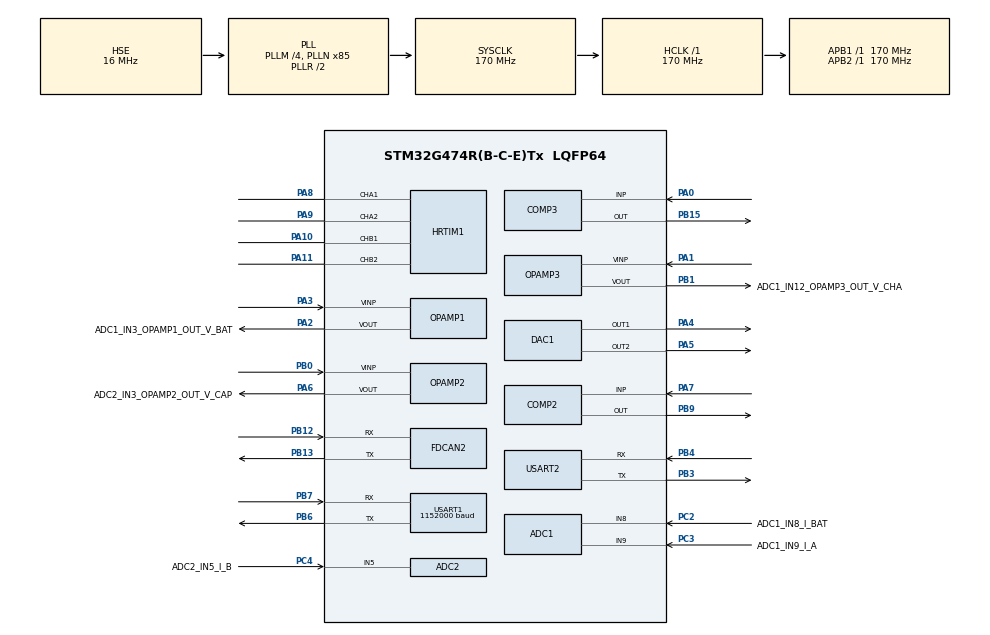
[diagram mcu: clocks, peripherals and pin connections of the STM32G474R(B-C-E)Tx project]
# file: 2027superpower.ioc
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ADC1.AWD1FilteringConfig=ADC_AWD_FILTERING_NONE
ADC1.AWD2ITMode=DISABLE
ADC1.AWDChannel-4\#ChannelRegularConversion=ADC_CHANNEL_8
ADC1.AWDChannel-5\#ChannelRegularConversion=ADC_CHANNEL_12
ADC1.Channel-3\#ChannelRegularConversion=ADC_CHANNEL_9
ADC1.Channel-4\#ChannelRegularConversion=ADC_CHANNEL_8
ADC1.Channel-5\#ChannelRegularConversion=ADC_CHANNEL_12
ADC1.Channel-7\#ChannelRegularConversion=ADC_CHANNEL_3
ADC1.DMAAccessModeView=ENABLE
ADC1.DMAContinuousRequests=ENABLE
ADC1.DiscontinuousConvMode=DISABLE
ADC1.EnableAnalogWatchDog1=true
ADC1.EnableAnalogWatchDog2=true
ADC1.EnableAnalogWatchDog3=true
ADC1.EnableInjectedConversion=DISABLE
ADC1.ExternalTrigConv=ADC_EXTERNALTRIG_HRTIM_TRG1
ADC1.Mode=ADC_DUALMODE_REGSIMULT
ADC1.MonitoredBy-4\#ChannelRegularConversion=ADC_ANALOGWATCHDOG_2
ADC1.MonitoredBy-5\#ChannelRegularConversion=ADC_ANALOGWATCHDOG_3
ADC1.NbrOfConversion=4
ADC1.NbrOfConversionFlag=1
ADC1.OffsetNumber-3\#ChannelRegularConversion=ADC_OFFSET_NONE
ADC1.OffsetNumber-4\#ChannelRegularConversion=ADC_OFFSET_NONE
ADC1.OffsetNumber-5\#ChannelRegularConversion=ADC_OFFSET_NONE
ADC1.OffsetNumber-7\#ChannelRegularConversion=ADC_OFFSET_NONE
ADC1.Overrun=ADC_OVR_DATA_OVERWRITTEN
ADC1.Rank-3\#ChannelRegularConversion=1
ADC1.Rank-4\#ChannelRegularConversion=2
ADC1.Rank-5\#ChannelRegularConversion=3
ADC1.Rank-7\#ChannelRegularConversion=4
ADC1.Rank1_Channel=ADC_CHANNEL_3
ADC1.RegFilteringConfig-4\#ChannelRegularConversion=ADC_AWD_FILTERING_NONE
ADC1.RegFilteringConfig-5\#ChannelRegularConversion=ADC_AWD_FILTERING_NONE
ADC1.SamplingTime-3\#ChannelRegularConversion=ADC_SAMPLETIME_12CYCLES_5
ADC1.SamplingTime-4\#ChannelRegularConversion=ADC_SAMPLETIME_12CYCLES_5
ADC1.SamplingTime-5\#ChannelRegularConversion=ADC_SAMPLETIME_12CYCLES_5
ADC1.SamplingTime-7\#ChannelRegularConversion=ADC_SAMPLETIME_12CYCLES_5
ADC1.WDG2ChannelR2=ADC_CHANNEL_8
ADC1.WDG3ChannelR3=ADC_CHANNEL_12
ADC1.WatchdogChannel=ADC_CHANNEL_9
ADC1.WatchdogMode2=ADC_ANALOGWATCHDOG_SINGLE_REGINJEC
ADC1.WatchdogMode3=ADC_ANALOGWATCHDOG_SINGLE_REGINJEC
ADC1.master=1
ADC2.AWD1FilteringConfig=ADC_AWD_FILTERING_NONE
ADC2.AWDChannel-2\#ChannelRegularConversion=ADC_CHANNEL_3
ADC2.Channel-0\#ChannelRegularConversion=ADC_CHANNEL_5
ADC2.Channel-1\#ChannelRegularConversion=ADC_CHANNEL_5
ADC2.Channel-2\#ChannelRegularConversion=ADC_CHANNEL_3
ADC2.Channel-4\#ChannelRegularConversion=ADC_CHANNEL_3
ADC2.DMAAccessModeView=ENABLE
ADC2.EnableAnalogWatchDog1=true
ADC2.EnableAnalogWatchDog2=true
ADC2.EnableAnalogWatchDog3=true
ADC2.Mode=ADC_DUALMODE_REGSIMULT
ADC2.MonitoredBy-2\#ChannelRegularConversion=ADC_ANALOGWATCHDOG_2
ADC2.NbrOfConversion=4
ADC2.NbrOfConversionFlag=1
ADC2.OffsetNumber-0\#ChannelRegularConversion=ADC_OFFSET_NONE
ADC2.OffsetNumber-1\#ChannelRegularConversion=ADC_OFFSET_NONE
ADC2.OffsetNumber-2\#ChannelRegularConversion=ADC_OFFSET_NONE
ADC2.OffsetNumber-4\#ChannelRegularConversion=ADC_OFFSET_NONE
ADC2.OversamplingMode=DISABLE
ADC2.Rank-0\#ChannelRegularConversion=1
ADC2.Rank-1\#ChannelRegularConversion=2
ADC2.Rank-2\#ChannelRegularConversion=3
ADC2.Rank-4\#ChannelRegularConversion=4
ADC2.RegFilteringConfig-2\#ChannelRegularConversion=ADC_AWD_FILTERING_NONE
ADC2.SamplingTime-0\#ChannelRegularConversion=ADC_SAMPLETIME_12CYCLES_5
ADC2.SamplingTime-1\#ChannelRegularConversion=ADC_SAMPLETIME_12CYCLES_5
ADC2.SamplingTime-2\#ChannelRegularConversion=ADC_SAMPLETIME_12CYCLES_5
ADC2.SamplingTime-4\#ChannelRegularConversion=ADC_SAMPLETIME_12CYCLES_5
ADC2.WDG2ChannelR3=ADC_CHANNEL_3
ADC2.WatchdogChannel=ADC_CHANNEL_5
ADC2.WatchdogMode=ADC_ANALOGWATCHDOG_SINGLE_REG
ADC2.WatchdogMode2=ADC_ANALOGWATCHDOG_SINGLE_REGINJEC
ADC2.WatchdogMode3=ADC_ANALOGWATCHDOG_SINGLE_REGINJEC
ADC5.Channel-0\#ChannelRegularConversion=ADC_CHANNEL_VREFINT
ADC5.Channel-1\#ChannelRegularConversion=ADC_CHANNEL_TEMPSENSOR_ADC5
ADC5.ContinuousConvMode=ENABLE
ADC5.DMAContinuousRequests=ENABLE
ADC5.NbrOfConversion=2
ADC5.NbrOfConversionFlag=1
ADC5.OffsetNumber-0\#ChannelRegularConversion=ADC_OFFSET_NONE
ADC5.OffsetNumber-1\#ChannelRegularConversion=ADC_OFFSET_NONE
ADC5.Overrun=ADC_OVR_DATA_OVERWRITTEN
ADC5.OversamplingMode=ENABLE
ADC5.Rank-0\#ChannelRegularConversion=1
ADC5.Rank-1\#ChannelRegularConversion=2
ADC5.Ratio=ADC_OVERSAMPLING_RATIO_256
ADC5.RightBitShift=ADC_RIGHTBITSHIFT_8
ADC5.SamplingTime-0\#ChannelRegularConversion=ADC_SAMPLETIME_640CYCLES_5
ADC5.SamplingTime-1\#ChannelRegularConversion=ADC_SAMPLETIME_640CYCLES_5
COMP2.OutputPol=COMP_OUTPUTPOL_NONINVERTED
DAC1.DAC_Channel-DAC_OUT2_ExtAndInt=DAC_CHANNEL_2
DAC1.DAC_HighFrequency_OUT1-DAC_OUT1_ExtAndInt=DAC_HIGH_FREQUENCY_INTERFACE_MODE_ABOVE_160MHZ
DAC1.DAC_Trigger2_OUT1-DAC_OUT1_ExtAndInt=DAC_TRIGGER_HRTIM_STEP_TRG2
DAC1.DAC_Trigger2_OUT2-DAC_OUT2_ExtAndInt=DAC_TRIGGER_HRTIM_STEP_TRG1
DAC1.DAC_Trigger_OUT1-DAC_OUT1_ExtAndInt=DAC_TRIGGER_HRTIM_RST_TRG2
DAC1.DAC_Trigger_OUT2-DAC_OUT2_ExtAndInt=DAC_TRIGGER_HRTIM_RST_TRG1
DAC1.WaveGeneration_OUT1-DAC_OUT1_ExtAndInt=SawtoothWaveGenerate
Dma.ADC1.4.Direction=DMA_PERIPH_TO_MEMORY
Dma.ADC1.4.EventEnable=DISABLE
Dma.ADC1.4.Instance=DMA1_Channel1
Dma.ADC1.4.MemDataAlignment=DMA_MDATAALIGN_WORD
Dma.ADC1.4.MemInc=DMA_MINC_ENABLE
Dma.ADC1.4.Mode=DMA_CIRCULAR
Dma.ADC1.4.PeriphDataAlignment=DMA_PDATAALIGN_WORD
Dma.ADC1.4.PeriphInc=DMA_PINC_DISABLE
Dma.ADC1.4.Polarity=HAL_DMAMUX_REQ_GEN_RISING
Dma.ADC1.4.Priority=DMA_PRIORITY_VERY_HIGH
Dma.ADC1.4.RequestNumber=1
Dma.ADC1.4.SignalID=NONE
Dma.ADC1.4.SyncEnable=DISABLE
Dma.ADC1.4.SyncPolarity=HAL_DMAMUX_SYNC_NO_EVENT
Dma.ADC1.4.SyncRequestNumber=1
Dma.ADC1.4.SyncSignalID=NONE
Dma.ADC5.5.Direction=DMA_PERIPH_TO_MEMORY
Dma.ADC5.5.EventEnable=DISABLE
Dma.ADC5.5.Instance=DMA1_Channel6
Dma.ADC5.5.MemDataAlignment=DMA_MDATAALIGN_HALFWORD
Dma.ADC5.5.MemInc=DMA_MINC_ENABLE
Dma.ADC5.5.Mode=DMA_CIRCULAR
Dma.ADC5.5.PeriphDataAlignment=DMA_PDATAALIGN_HALFWORD
Dma.ADC5.5.PeriphInc=DMA_PINC_DISABLE
Dma.ADC5.5.Polarity=HAL_DMAMUX_REQ_GEN_RISING
Dma.ADC5.5.Priority=DMA_PRIORITY_LOW
Dma.ADC5.5.RequestNumber=1
Dma.ADC5.5.SignalID=NONE
Dma.ADC5.5.SyncEnable=DISABLE
Dma.ADC5.5.SyncPolarity=HAL_DMAMUX_SYNC_NO_EVENT
Dma.ADC5.5.SyncRequestNumber=1
Dma.ADC5.5.SyncSignalID=NONE
Dma.Request0=USART1_RX
Dma.Request1=USART1_TX
Dma.Request2=USART2_RX
Dma.Request3=USART2_TX
Dma.Request4=ADC1
Dma.Request5=ADC5
Dma.USART1_RX.0.Direction=DMA_PERIPH_TO_MEMORY
Dma.USART1_RX.0.EventEnable=DISABLE
Dma.USART1_RX.0.Instance=DMA1_Channel5
Dma.USART1_RX.0.MemDataAlignment=DMA_MDATAALIGN_BYTE
Dma.USART1_RX.0.MemInc=DMA_MINC_ENABLE
Dma.USART1_RX.0.Mode=DMA_NORMAL
Dma.USART1_RX.0.PeriphDataAlignment=DMA_PDATAALIGN_BYTE
Dma.USART1_RX.0.PeriphInc=DMA_PINC_DISABLE
Dma.USART1_RX.0.Polarity=HAL_DMAMUX_REQ_GEN_RISING
Dma.USART1_RX.0.Priority=DMA_PRIORITY_LOW
Dma.USART1_RX.0.RequestNumber=1
Dma.USART1_RX.0.SignalID=NONE
Dma.USART1_RX.0.SyncEnable=DISABLE
Dma.USART1_RX.0.SyncPolarity=HAL_DMAMUX_SYNC_NO_EVENT
Dma.USART1_RX.0.SyncRequestNumber=1
Dma.USART1_RX.0.SyncSignalID=NONE
Dma.USART1_TX.1.Direction=DMA_MEMORY_TO_PERIPH
Dma.USART1_TX.1.EventEnable=DISABLE
Dma.USART1_TX.1.Instance=DMA1_Channel2
Dma.USART1_TX.1.MemDataAlignment=DMA_MDATAALIGN_BYTE
Dma.USART1_TX.1.MemInc=DMA_MINC_ENABLE
Dma.USART1_TX.1.Mode=DMA_NORMAL
Dma.USART1_TX.1.PeriphDataAlignment=DMA_PDATAALIGN_BYTE
Dma.USART1_TX.1.PeriphInc=DMA_PINC_DISABLE
Dma.USART1_TX.1.Polarity=HAL_DMAMUX_REQ_GEN_RISING
Dma.USART1_TX.1.Priority=DMA_PRIORITY_LOW
Dma.USART1_TX.1.RequestNumber=1
Dma.USART1_TX.1.SignalID=NONE
Dma.USART1_TX.1.SyncEnable=DISABLE
Dma.USART1_TX.1.SyncPolarity=HAL_DMAMUX_SYNC_NO_EVENT
Dma.USART1_TX.1.SyncRequestNumber=1
Dma.USART1_TX.1.SyncSignalID=NONE
Dma.USART2_RX.2.Direction=DMA_PERIPH_TO_MEMORY
Dma.USART2_RX.2.EventEnable=DISABLE
Dma.USART2_RX.2.Instance=DMA1_Channel3
Dma.USART2_RX.2.MemDataAlignment=DMA_MDATAALIGN_BYTE
Dma.USART2_RX.2.MemInc=DMA_MINC_ENABLE
Dma.USART2_RX.2.Mode=DMA_NORMAL
Dma.USART2_RX.2.PeriphDataAlignment=DMA_PDATAALIGN_BYTE
Dma.USART2_RX.2.PeriphInc=DMA_PINC_DISABLE
Dma.USART2_RX.2.Polarity=HAL_DMAMUX_REQ_GEN_RISING
Dma.USART2_RX.2.Priority=DMA_PRIORITY_LOW
Dma.USART2_RX.2.RequestNumber=1
Dma.USART2_RX.2.SignalID=NONE
Dma.USART2_RX.2.SyncEnable=DISABLE
Dma.USART2_RX.2.SyncPolarity=HAL_DMAMUX_SYNC_NO_EVENT
Dma.USART2_RX.2.SyncRequestNumber=1
Dma.USART2_RX.2.SyncSignalID=NONE
Dma.USART2_TX.3.Direction=DMA_MEMORY_TO_PERIPH
Dma.USART2_TX.3.EventEnable=DISABLE
Dma.USART2_TX.3.Instance=DMA1_Channel4
Dma.USART2_TX.3.MemDataAlignment=DMA_MDATAALIGN_BYTE
Dma.USART2_TX.3.MemInc=DMA_MINC_ENABLE
Dma.USART2_TX.3.Mode=DMA_NORMAL
Dma.USART2_TX.3.PeriphDataAlignment=DMA_PDATAALIGN_BYTE
Dma.USART2_TX.3.PeriphInc=DMA_PINC_DISABLE
Dma.USART2_TX.3.Polarity=HAL_DMAMUX_REQ_GEN_RISING
Dma.USART2_TX.3.Priority=DMA_PRIORITY_LOW
Dma.USART2_TX.3.RequestNumber=1
Dma.USART2_TX.3.SignalID=NONE
Dma.USART2_TX.3.SyncEnable=DISABLE
Dma.USART2_TX.3.SyncPolarity=HAL_DMAMUX_SYNC_NO_EVENT
Dma.USART2_TX.3.SyncRequestNumber=1
Dma.USART2_TX.3.SyncSignalID=NONE
FDCAN2.CalculateBaudRateNominal=3541666
FDCAN2.CalculateTimeBitNominal=282
FDCAN2.CalculateTimeQuantumNominal=94.11764705882354
HRTIM1.ADCTrigger1_Source1=HRTIM_ADCTRIGGEREVENT13_MASTER_CMP1
HRTIM1.ADCTrigger_Id1=HRTIM_ADCTRIGGER_1
HRTIM1.ADCTrigger_Id2=__NULL
HRTIM1.BlankingSourceFaultLine1=__NULL
HRTIM1.BlankingSourceFaultLine2=__NULL
HRTIM1.BlankingSourceFaultLine3=__NULL
HRTIM1.BlankingSourceFaultLine4=__NULL
HRTIM1.BlankingSourceFaultLine5=__NULL
HRTIM1.CaptureUnit2-Output_TB1TB2=__NULL
HRTIM1.CompareUnit1-MasterTimer=HRTIM_COMPAREUNIT_1
HRTIM1.CompareUnit1-Output_TA1TA2=HRTIM_COMPAREUNIT_1
HRTIM1.CompareUnit1-Output_TB1TB2=HRTIM_COMPAREUNIT_1
HRTIM1.CompareUnit2-MasterTimer=HRTIM_COMPAREUNIT_2
HRTIM1.CompareUnit2-Output_TA1TA2=HRTIM_COMPAREUNIT_2
HRTIM1.CompareUnit2-Output_TB1TB2=HRTIM_COMPAREUNIT_2
HRTIM1.CompareUnit3-Output_TA1TA2=HRTIM_COMPAREUNIT_3
HRTIM1.CompareUnit3-Output_TB1TB2=HRTIM_COMPAREUNIT_3
HRTIM1.CompareUnit4-Output_TA1TA2=HRTIM_COMPAREUNIT_4
HRTIM1.CompareUnit4-Output_TB1TB2=HRTIM_COMPAREUNIT_4
HRTIM1.CompareValue1-MasterTimer=10880/4-800
HRTIM1.CompareValue1-Output_TA1TA2=100
HRTIM1.CompareValue1-Output_TB1TB2=100
HRTIM1.CompareValue2-MasterTimer=10880
HRTIM1.CompareValue2-Output_TA1TA2=1088
HRTIM1.CompareValue2-Output_TB1TB2=1088
HRTIM1.CompareValue3-Output_TA1TA2=10880+5440
HRTIM1.CompareValue3-Output_TB1TB2=10880
HRTIM1.CompareValue4-Output_TA1TA2=1306
HRTIM1.CompareValue4-Output_TB1TB2=1306
HRTIM1.CounterFaultLine1=0
HRTIM1.CounterFaultLine2=0
HRTIM1.CounterFaultLine3=0
HRTIM1.CounterFaultLine4=0
HRTIM1.CounterFaultLine5=0
HRTIM1.DeadTimeInsertion-Output_TA1TA2=HRTIM_TIMDEADTIMEINSERTION_ENABLED
HRTIM1.DeadTimeInsertion-Output_TB1TB2=HRTIM_TIMDEADTIMEINSERTION_ENABLED
HRTIM1.DualChannelDacEnableFake_TA-Output_TA1TA2=HRTIM_TIMER_DCDE_ENABLED_FAKE1
HRTIM1.DualChannelDacEnableFake_TB-Output_TB1TB2=HRTIM_TIMER_DCDE_ENABLED_FAKE1
HRTIM1.Event1-Output_TA1TA2=__NULL
HRTIM1.Event1-Output_TB1TB2=__NULL
HRTIM1.Event6-Output_TA1TA2=HRTIM_EVENT_6
HRTIM1.Event6-Output_TB1TB2=__NULL
HRTIM1.Event8-Output_TA1TA2=__NULL
HRTIM1.Event8-Output_TB1TB2=HRTIM_EVENT_8
HRTIM1.Event_EEV1=HRTIM_EVENT_1
HRTIM1.Event_EEV10=__NULL
HRTIM1.Event_EEV2=HRTIM_EVENT_2
HRTIM1.Event_EEV3=HRTIM_EVENT_3
HRTIM1.Event_EEV4=HRTIM_EVENT_4
HRTIM1.Event_EEV5=HRTIM_EVENT_5
HRTIM1.Event_EEV6=HRTIM_EVENT_6
HRTIM1.Event_EEV7=__NULL
HRTIM1.Event_EEV8=HRTIM_EVENT_8
HRTIM1.Event_EEV9=__NULL
HRTIM1.FallingLock-Output_TA1TA2=HRTIM_TIMDEADTIME_FALLINGLOCK_READONLY
HRTIM1.FallingLock-Output_TB1TB2=HRTIM_TIMDEADTIME_FALLINGLOCK_READONLY
HRTIM1.FallingSignLock-Output_TA1TA2=HRTIM_TIMDEADTIME_FALLINGSIGNLOCK_READONLY
HRTIM1.FallingSignLock-Output_TB1TB2=HRTIM_TIMDEADTIME_FALLINGSIGNLOCK_READONLY
HRTIM1.FallingValue-Output_TA1TA2=68
HRTIM1.FallingValue-Output_TB1TB2=68
HRTIM1.FaultEnable_Source1-Output_TA1TA2=HRTIM_TIMFAULTENABLE_FAULT1
HRTIM1.FaultEnable_Source1-Output_TB1TB2=HRTIM_TIMFAULTENABLE_FAULT1
HRTIM1.FaultEnable_Source2-Output_TA1TA2=HRTIM_TIMFAULTENABLE_FAULT2
HRTIM1.FaultEnable_Source2-Output_TB1TB2=HRTIM_TIMFAULTENABLE_FAULT2
HRTIM1.FaultEnable_Source3-Output_TA1TA2=HRTIM_TIMFAULTENABLE_FAULT3
HRTIM1.FaultEnable_Source3-Output_TB1TB2=HRTIM_TIMFAULTENABLE_FAULT3
HRTIM1.FaultEnable_Source4-Output_TA1TA2=HRTIM_TIMFAULTENABLE_FAULT4
HRTIM1.FaultEnable_Source4-Output_TB1TB2=HRTIM_TIMFAULTENABLE_FAULT4
HRTIM1.FaultEnable_Source5-Output_TA1TA2=HRTIM_TIMFAULTENABLE_FAULT5
HRTIM1.FaultEnable_Source5-Output_TB1TB2=HRTIM_TIMFAULTENABLE_FAULT5
HRTIM1.FaultLevel1-Output_TA1TA2=HRTIM_OUTPUTFAULTLEVEL_INACTIVE
HRTIM1.FaultLevel1-Output_TB1TB2=HRTIM_OUTPUTFAULTLEVEL_INACTIVE
HRTIM1.FaultLevel2-Output_TA1TA2=HRTIM_OUTPUTFAULTLEVEL_INACTIVE
HRTIM1.FaultLevel2-Output_TB1TB2=HRTIM_OUTPUTFAULTLEVEL_INACTIVE
HRTIM1.Fault_Line1=HRTIM_FAULT_1
HRTIM1.Fault_Line2=HRTIM_FAULT_2
HRTIM1.Fault_Line3=HRTIM_FAULT_3
HRTIM1.Fault_Line4=HRTIM_FAULT_4
HRTIM1.Fault_Line5=HRTIM_FAULT_5
HRTIM1.Fault_Line6=__NULL
HRTIM1.Filter6-Output_TA1TA2=HRTIM_TIMEEVFLT_BLANKINGCMP4
HRTIM1.Filter8-Output_TB1TB2=HRTIM_TIMEEVFLT_BLANKINGCMP4
HRTIM1.HRTIMInterruptResquests1=HRTIM_IT_NONE
HRTIM1.HRTIMInterruptResquests2=HRTIM_IT_NONE
HRTIM1.HRTIMInterruptResquests3=HRTIM_IT_NONE
HRTIM1.HRTIMInterruptResquests4=HRTIM_IT_NONE
HRTIM1.HRTIMInterruptResquests5=HRTIM_IT_NONE
HRTIM1.InterruptRequests1-Output_TA1TA2=HRTIM_TIM_IT_REP
HRTIM1.InterruptRequests1_Master=HRTIM_MASTER_IT_MREP
HRTIM1.NumberADCTriggerSource1=1
HRTIM1.NumberFaultEnable-Output_TA1TA2=5
HRTIM1.NumberFaultEnable-Output_TB1TB2=5
HRTIM1.NumberInterruptRequests-Output_TA1TA2=1
HRTIM1.NumberInterruptRequests_Master-MasterTimer=1
HRTIM1.NumberResetSource1-Output_TA1TA2=2
HRTIM1.NumberResetSource1-Output_TB1TB2=2
HRTIM1.NumberResetTrigger-Output_TA1TA2=1
HRTIM1.NumberResetTrigger-Output_TB1TB2=1
HRTIM1.NumberSetSource1-Output_TA1TA2=1
HRTIM1.NumberSetSource1-Output_TB1TB2=1
HRTIM1.ORingUpdateSource_ADCTrigger1=HRTIM_ADCTRIGGERUPDATE_MASTER
HRTIM1.Periode_MASTER=21760
HRTIM1.Periode_TA=21760
HRTIM1.Periode_TB=21760
HRTIM1.Polarity1-Output_TA1TA2=HRTIM_OUTPUTPOLARITY_HIGH
HRTIM1.Polarity1-Output_TB1TB2=HRTIM_OUTPUTPOLARITY_HIGH
HRTIM1.Polarity_EEV6=HRTIM_EVENTPOLARITY_HIGH
HRTIM1.Polarity_EEV8=HRTIM_EVENTPOLARITY_LOW
HRTIM1.PreloadEnable-Output_TA1TA2=HRTIM_PRELOAD_ENABLED
HRTIM1.PreloadEnable-Output_TB1TB2=HRTIM_PRELOAD_ENABLED
HRTIM1.RepetitionCounter-MasterTimer=4-1
HRTIM1.RepetitionCounter-Output_TA1TA2=250-1
HRTIM1.RepetitionCounter-Output_TB1TB2=0
HRTIM1.ResetModeFaultLine1=HRTIM_FAULTCOUNTERRST_CONDITIONAL
HRTIM1.ResetModeFaultLine2=HRTIM_FAULTCOUNTERRST_CONDITIONAL
HRTIM1.ResetModeFaultLine3=HRTIM_FAULTCOUNTERRST_CONDITIONAL
HRTIM1.ResetModeFaultLine4=HRTIM_FAULTCOUNTERRST_CONDITIONAL
HRTIM1.ResetModeFaultLine5=HRTIM_FAULTCOUNTERRST_CONDITIONAL
HRTIM1.ResetOutput1_Source1-Output_TA1TA2=HRTIM_OUTPUTSET_EEV_6
HRTIM1.ResetOutput1_Source1-Output_TB1TB2=HRTIM_OUTPUTRESET_EEV_8
HRTIM1.ResetOutput1_Source2-Output_TA1TA2=HRTIM_OUTPUTRESET_TIMCMP3
HRTIM1.ResetOutput1_Source2-Output_TB1TB2=HRTIM_OUTPUTRESET_TIMCMP3
HRTIM1.ResetTrigger1-Output_TA1TA2=HRTIM_TIMRESETTRIGGER_MASTER_CMP2
HRTIM1.ResetTrigger1-Output_TB1TB2=HRTIM_TIMRESETTRIGGER_MASTER_PER
HRTIM1.ResetUpdate-Output_TA1TA2=HRTIM_TIMUPDATEONRESET_ENABLED
HRTIM1.ResetUpdate-Output_TB1TB2=HRTIM_TIMUPDATEONRESET_ENABLED
HRTIM1.RisingLock-Output_TA1TA2=HRTIM_TIMDEADTIME_RISINGLOCK_READONLY
HRTIM1.RisingLock-Output_TB1TB2=HRTIM_TIMDEADTIME_RISINGLOCK_READONLY
HRTIM1.RisingSignLock-Output_TA1TA2=HRTIM_TIMDEADTIME_RISINGSIGNLOCK_READONLY
HRTIM1.RisingSignLock-Output_TB1TB2=HRTIM_TIMDEADTIME_RISINGSIGNLOCK_READONLY
HRTIM1.RisingValue-Output_TA1TA2=68
HRTIM1.RisingValue-Output_TB1TB2=68
HRTIM1.SetOutput1_Source1-Output_TA1TA2=HRTIM_OUTPUTSET_TIMCMP1
HRTIM1.SetOutput1_Source1-Output_TB1TB2=HRTIM_OUTPUTSET_TIMCMP1
HRTIM1.Source_EEV1=HRTIM_EEV1SRC_ADC1_AWD1
HRTIM1.Source_EEV2=HRTIM_EEV2SRC_ADC1_AWD2
HRTIM1.Source_EEV3=HRTIM_EEV3SRC_ADC1_AWD3
HRTIM1.Source_EEV4=HRTIM_EEV4SRC_ADC2_AWD1
HRTIM1.Source_EEV5=HRTIM_EEV5SRC_ADC2_AWD2
HRTIM1.Source_EEV6=HRTIM_EEV6SRC_COMP2_OUT
HRTIM1.Source_EEV8=HRTIM_EEV8SRC_COMP3_OUT
HRTIM1.Source_FaultLine1=HRTIM_FAULTSOURCE_EEVINPUT
HRTIM1.Source_FaultLine2=HRTIM_FAULTSOURCE_EEVINPUT
HRTIM1.Source_FaultLine3=HRTIM_FAULTSOURCE_EEVINPUT
HRTIM1.Source_FaultLine4=HRTIM_FAULTSOURCE_EEVINPUT
HRTIM1.Source_FaultLine5=HRTIM_FAULTSOURCE_EEVINPUT
Mcu.Family=STM32G4
Mcu.Name=STM32G474R(B-C-E)Tx
Mcu.Package=LQFP64
NVIC.DMA1_Channel1_IRQn=true\:0\:0\:false\:false\:true\:false\:true\:true
NVIC.DMA1_Channel2_IRQn=true\:0\:0\:false\:false\:true\:false\:true\:true
NVIC.DMA1_Channel3_IRQn=true\:0\:0\:false\:false\:true\:false\:true\:true
NVIC.DMA1_Channel4_IRQn=true\:0\:0\:false\:false\:true\:false\:true\:true
NVIC.DMA1_Channel5_IRQn=true\:0\:0\:false\:false\:true\:false\:true\:true
NVIC.DMA1_Channel6_IRQn=true\:0\:0\:false\:false\:true\:false\:true\:true
NVIC.HRTIM1_Master_IRQn=true\:1\:0\:true\:false\:true\:true\:true\:true
NVIC.HRTIM1_TIMA_IRQn=true\:2\:0\:true\:false\:true\:true\:true\:true
NVIC.PriorityGroup=NVIC_PRIORITYGROUP_4
NVIC.USART1_IRQn=true\:3\:0\:true\:false\:true\:true\:true\:true
NVIC.USART2_IRQn=true\:3\:0\:true\:false\:true\:true\:true\:true
OPAMP1.PowerMode=OPAMP_POWERMODE_HIGHSPEED
OPAMP2.PowerMode=OPAMP_POWERMODE_HIGHSPEED
OPAMP3.PowerMode=OPAMP_POWERMODE_HIGHSPEED
PA0.Mode=INP
PA0.Signal=COMP3_INP
PA1.Mode=Follower
PA1.Signal=OPAMP3_VINP
PA10.Mode=Output_TB1TB2
PA10.Signal=HRTIM1_CHB1
PA11.Mode=Output_TB1TB2
PA11.Signal=HRTIM1_CHB2
PA2.GPIO_Label=ADC1_IN3_OPAMP1_OUT_V_BAT
PA2.Signal=SharedAnalog_PA2
PA3.Mode=Follower
PA3.Signal=OPAMP1_VINP
PA4.Signal=COMP_DAC11_group
PA5.Signal=COMP_DAC12_group
PA6.GPIO_Label=ADC2_IN3_OPAMP2_OUT_V_CAP
PA6.Signal=SharedAnalog_PA6
PA7.Mode=INP
PA7.Signal=COMP2_INP
PA8.Mode=Output_TA1TA2
PA8.Signal=HRTIM1_CHA1
PA9.Mode=Output_TA1TA2
PA9.Signal=HRTIM1_CHA2
PB0.Mode=Follower
PB0.Signal=OPAMP2_VINP
PB1.GPIO_Label=ADC1_IN12_OPAMP3_OUT_V_CHA
PB1.Signal=SharedAnalog_PB1
PB12.Mode=FDCAN_Activate
PB12.Signal=FDCAN2_RX
PB13.Mode=FDCAN_Activate
PB13.Signal=FDCAN2_TX
PB15.Mode=ExternalOutput
PB15.Signal=COMP3_OUT
PB3.Mode=Asynchronous
PB3.Signal=USART2_TX
PB4.Mode=Asynchronous
PB4.Signal=USART2_RX
PB6.Mode=Asynchronous
PB6.Signal=USART1_TX
PB7.Mode=Asynchronous
PB7.Signal=USART1_RX
PB9.Mode=ExternalOutput
PB9.Signal=COMP2_OUT
PC14-OSC32_IN.Mode=LSE-External-Oscillator
PC14-OSC32_IN.Signal=RCC_OSC32_IN
PC15-OSC32_OUT.Mode=LSE-External-Oscillator
PC15-OSC32_OUT.Signal=RCC_OSC32_OUT
PC2.GPIO_Label=ADC1_IN8_I_BAT
PC2.Mode=IN8-Single-Ended
PC2.Signal=ADC1_IN8
PC3.GPIO_Label=ADC1_IN9_I_A
PC3.Mode=IN9-Single-Ended
PC3.Signal=ADC1_IN9
PC4.GPIO_Label=ADC2_IN5_I_B
PC4.Mode=IN5-Single-Ended
PC4.Signal=ADC2_IN5
PF0-OSC_IN.Mode=HSE-External-Oscillator
PF0-OSC_IN.Signal=RCC_OSC_IN
PF1-OSC_OUT.Mode=HSE-External-Oscillator
PF1-OSC_OUT.Signal=RCC_OSC_OUT
ProjectManager.HeapSize=0x200
ProjectManager.StackSize=0x400
ProjectManager.TargetToolchain=MDK-ARM V5.32
RCC.ADC12Freq_Value=170000000
RCC.ADC345Freq_Value=170000000
RCC.AHBFreq_Value=170000000
RCC.APB1Freq_Value=170000000
RCC.APB1TimFreq_Value=170000000
RCC.APB2Freq_Value=170000000
RCC.APB2TimFreq_Value=170000000
RCC.CortexFreq_Value=170000000
RCC.EXTERNAL_CLOCK_VALUE=12288000
RCC.HCLKFreq_Value=170000000
RCC.HSE_VALUE=16000000
RCC.HSI48_VALUE=48000000
RCC.HSI_VALUE=16000000
RCC.PLLM=RCC_PLLM_DIV4
RCC.PLLN=85
RCC.PLLSourceVirtual=RCC_PLLSOURCE_HSE
RCC.SYSCLKFreq_VALUE=170000000
RCC.SYSCLKSource=RCC_SYSCLKSOURCE_PLLCLK
RCC.USBFreq_Value=170000000
RCC.VCOOutputFreq_Value=340000000
SH.COMP_DAC11_group.0=DAC1_OUT1,DAC_OUT1_ExtAndInt
SH.COMP_DAC12_group.0=DAC1_OUT2,DAC_OUT2_ExtAndInt
SH.SharedAnalog_PA2.0=OPAMP1_VOUT,Follower
SH.SharedAnalog_PA2.1=ADC1_IN3,IN3-Single-Ended
SH.SharedAnalog_PA6.0=OPAMP2_VOUT,Follower
SH.SharedAnalog_PA6.1=ADC2_IN3,IN3-Single-Ended
SH.SharedAnalog_PB1.0=OPAMP3_VOUT,Follower
SH.SharedAnalog_PB1.1=ADC1_IN12,IN12-Single-Ended
USART1.BaudRate=1152000
USART1.VirtualMode-Asynchronous=VM_ASYNC
USART2.VirtualMode-Asynchronous=VM_ASYNC
VP_ADC5_TempSens_Input.Mode=IN-TempSens
VP_ADC5_Vref_Input.Mode=IN-Vrefint
VP_COMP2_VS_DAC1OUT2.Mode=INM_DAC1OUT2
VP_COMP3_VS_DAC1OUT1.Mode=INM_DAC1OUT1
VP_HRTIM1_VS_hrtimMasterTimerNoOutput.Mode=MasterTimer
VP_SYS_VS_DBSignals.Mode=DisableDeadBatterySignals
board=custom

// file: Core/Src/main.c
/* USER CODE BEGIN Header */
/**
  ******************************************************************************
  * @file           : main.c
  * @brief          : Main program body
  ******************************************************************************
  * @attention
  *
  * Copyright (c) 2026 STMicroelectronics.
  * All rights reserved.
  *
  * This software is licensed under terms that can be found in the LICENSE file
  * in the root directory of this software component.
  * If no LICENSE file comes with this software, it is provided AS-IS.
  *
  ******************************************************************************
  */
/* USER CODE END Header */
#include "main.h"
#include "adc.h"
#include "comp.h"
#include "dac.h"
#include "dma.h"
#include "fdcan.h"
#include "hrtim.h"
#include "opamp.h"
#include "usart.h"
#include "gpio.h"

/* USER CODE BEGIN Includes */
#include "power_ctrl_task.h"
#include "bsp_dwt.h"

/* USER CODE END Includes */

void SystemClock_Config(void);

int main(void)
{

  /* MCU Configuration--------------------------------------------------------*/

  /* Reset of all peripherals, Initializes the Flash interface and the Systick. */
  HAL_Init();

  /* Configure the system clock */
  SystemClock_Config();

  /* Initialize all configured peripherals */
  MX_GPIO_Init();
  MX_DMA_Init();
  MX_HRTIM1_Init();
  MX_USART1_UART_Init();
  MX_USART2_UART_Init();
  MX_ADC1_Init();
  MX_ADC2_Init();
  MX_OPAMP1_Init();
  MX_OPAMP2_Init();
  MX_OPAMP3_Init();
  MX_COMP2_Init();
  MX_COMP3_Init();
  MX_DAC1_Init();
  MX_FDCAN2_Init();
  MX_ADC5_Init();
  /* USER CODE BEGIN 2 */
    SuperPower_Init();
  /* USER CODE END 2 */

  /* Infinite loop */
  /* USER CODE BEGIN WHILE */
  while (1)
  {
	  Bsp_DWT_Update();
    /* USER CODE END WHILE */

  }
}

void SystemClock_Config(void)
{
  RCC_OscInitTypeDef RCC_OscInitStruct = {0};
  RCC_ClkInitTypeDef RCC_ClkInitStruct = {0};

  /** Configure the main internal regulator output voltage
  */
  HAL_PWREx_ControlVoltageScaling(PWR_REGULATOR_VOLTAGE_SCALE1_BOOST);

  /** Initializes the RCC Oscillators according to the specified parameters
  * in the RCC_OscInitTypeDef structure.
  */
  RCC_OscInitStruct.OscillatorType = RCC_OSCILLATORTYPE_HSE;
  RCC_OscInitStruct.HSEState = RCC_HSE_ON;
  RCC_OscInitStruct.PLL.PLLState = RCC_PLL_ON;
  RCC_OscInitStruct.PLL.PLLSource = RCC_PLLSOURCE_HSE;
  RCC_OscInitStruct.PLL.PLLM = RCC_PLLM_DIV4;
  RCC_OscInitStruct.PLL.PLLN = 85;
  RCC_OscInitStruct.PLL.PLLP = RCC_PLLP_DIV2;
  RCC_OscInitStruct.PLL.PLLQ = RCC_PLLQ_DIV2;
  RCC_OscInitStruct.PLL.PLLR = RCC_PLLR_DIV2;
  if (HAL_RCC_OscConfig(&RCC_OscInitStruct) != HAL_OK)
  {
    Error_Handler();
  }

  /** Initializes the CPU, AHB and APB buses clocks
  */
  RCC_ClkInitStruct.ClockType = RCC_CLOCKTYPE_HCLK|RCC_CLOCKTYPE_SYSCLK
                              |RCC_CLOCKTYPE_PCLK1|RCC_CLOCKTYPE_PCLK2;
  RCC_ClkInitStruct.SYSCLKSource = RCC_SYSCLKSOURCE_PLLCLK;
  RCC_ClkInitStruct.AHBCLKDivider = RCC_SYSCLK_DIV1;
  RCC_ClkInitStruct.APB1CLKDivider = RCC_HCLK_DIV1;
  RCC_ClkInitStruct.APB2CLKDivider = RCC_HCLK_DIV1;

  if (HAL_RCC_ClockConfig(&RCC_ClkInitStruct, FLASH_LATENCY_4) != HAL_OK)
  {
    Error_Handler();
  }
}

void Error_Handler(void)
{
  __disable_irq();
  while (1)
  {
  }
}
